# STM32F40x register map
File version: 1.5
Registers are 32-bit, read-write, reset 0x0 unless marked. A register's access mark holds for its fields unless they carry their own. Offsets are from the block's base; [hi:lo] are bit positions; {n}, {i} and the like mark numbered series.

## RNG（随机数发生器） — 真随机数发生器 | Random number generator
Base 0x50060800
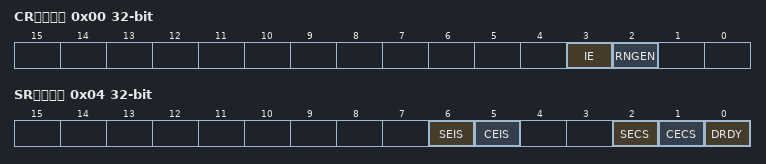
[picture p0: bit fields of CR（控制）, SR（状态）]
0x00 CR（控制） — 随机数使能/中断 | control register
  [3] IE — Interrupt enable
  [2] RNGEN — Random number generator enable
0x04 SR（状态） access per field — 数据就绪/错误标志 | status register
  [6] SEIS rw — Seed error interrupt status
  [5] CEIS rw — Clock error interrupt status
  [2] SECS ro — Seed error current status
  [1] CECS ro — Clock error current status
  [0] DRDY ro — Data ready
0x08 DR（数据） ro — 随机数输出 | data register
  [31:0] RNDATA — Random data

## DCMI（数字摄像头接口） — 数字摄像头接口：并行图像采集 | Digital camera interface
Base 0x50050000
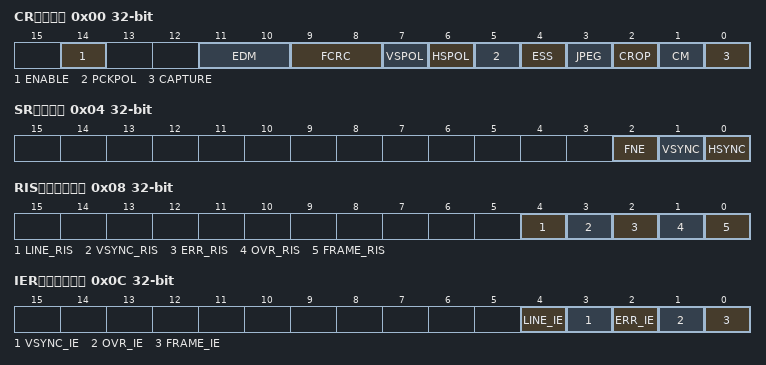
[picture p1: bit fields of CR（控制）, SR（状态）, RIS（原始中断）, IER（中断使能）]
0x00 CR（控制） — 捕获使能/模式/同步 | control register 1
  [14] ENABLE — DCMI enable
  [11:10] EDM — Extended data mode
  [9:8] FCRC — Frame capture rate control
  [7] VSPOL — Vertical synchronization polarity
  [6] HSPOL — Horizontal synchronization polarity
  [5] PCKPOL — Pixel clock polarity
  [4] ESS — Embedded synchronization select
  [3] JPEG — JPEG format
  [2] CROP — Crop feature
  [1] CM — Capture mode
  [0] CAPTURE — Capture enable
0x04 SR（状态） ro — FIFO/同步状态 | status register
  [2] FNE — FIFO not empty
  [1] VSYNC
  [0] HSYNC
0x08 RIS（原始中断） ro — 原始中断状态 | raw interrupt status register
  [4] LINE_RIS — Line raw interrupt status
  [3] VSYNC_RIS — VSYNC raw interrupt status
  [2] ERR_RIS — Synchronization error raw interrupt status
  [1] OVR_RIS — Overrun raw interrupt status
  [0] FRAME_RIS — Capture complete raw interrupt status
0x0C IER（中断使能） — 中断使能 | interrupt enable register
  [4] LINE_IE — Line interrupt enable
  [3] VSYNC_IE — VSYNC interrupt enable
  [2] ERR_IE — Synchronization error interrupt enable
  [1] OVR_IE — Overrun interrupt enable
  [0] FRAME_IE — Capture complete interrupt enable
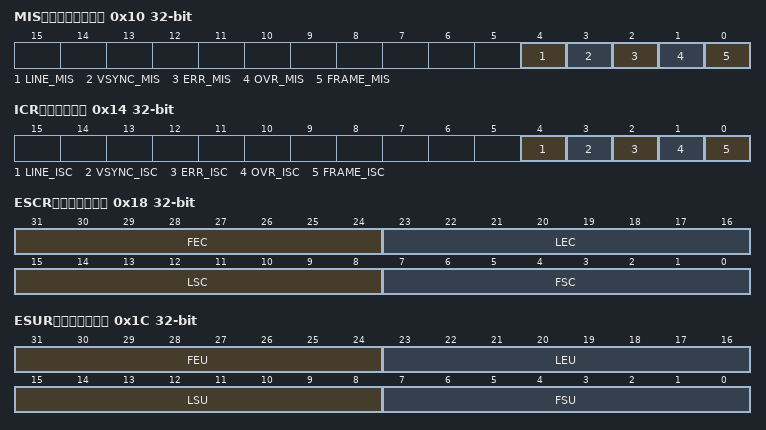
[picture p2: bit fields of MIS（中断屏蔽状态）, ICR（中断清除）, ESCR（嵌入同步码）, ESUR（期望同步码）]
0x10 MIS（中断屏蔽状态） ro — 屏蔽后中断状态 | masked interrupt status register
  [4] LINE_MIS — Line masked interrupt status
  [3] VSYNC_MIS — VSYNC masked interrupt status
  [2] ERR_MIS — Synchronization error masked interrupt status
  [1] OVR_MIS — Overrun masked interrupt status
  [0] FRAME_MIS — Capture complete masked interrupt status
0x14 ICR（中断清除） wo — 清除中断标志 | interrupt clear register
  [4] LINE_ISC — line interrupt status clear
  [3] VSYNC_ISC — Vertical synch interrupt status clear
  [2] ERR_ISC — Synchronization error interrupt status clear
  [1] OVR_ISC — Overrun interrupt status clear
  [0] FRAME_ISC — Capture complete interrupt status clear
0x18 ESCR（嵌入同步码） — 嵌入同步码配置 | embedded synchronization code register
  [31:24] FEC — Frame end delimiter code
  [23:16] LEC — Line end delimiter code
  [15:8] LSC — Line start delimiter code
  [7:0] FSC — Frame start delimiter code
0x1C ESUR（期望同步码） — 期望同步码配置 | embedded synchronization unmask register
  [31:24] FEU — Frame end delimiter unmask
  [23:16] LEU — Line end delimiter unmask
  [15:8] LSU — Line start delimiter unmask
  [7:0] FSU — Frame start delimiter unmask
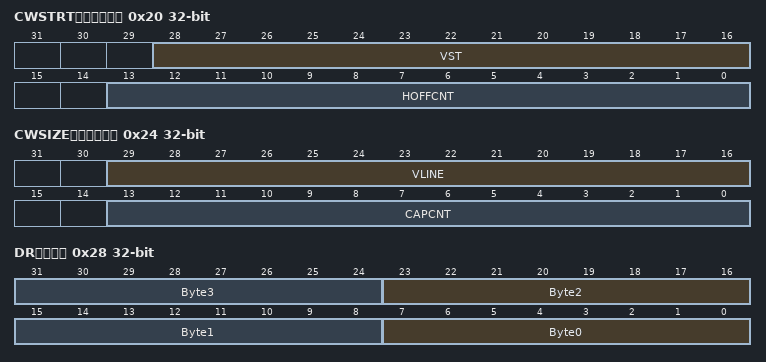
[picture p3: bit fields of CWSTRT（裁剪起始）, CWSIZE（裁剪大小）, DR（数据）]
0x20 CWSTRT（裁剪起始） — 裁剪窗口起始 | crop window start
  [28:16] VST — Vertical start line count
  [13:0] HOFFCNT — Horizontal offset count
0x24 CWSIZE（裁剪大小） — 裁剪窗口大小 | crop window size
  [29:16] VLINE — Vertical line count
  [13:0] CAPCNT — Capture count
0x28 DR（数据） ro — 像素数据 | data register
  [8n+7:8n] Byte{n} (n=0..3) — Data byte {n}

## DBG（调试支持） — 调试支持单元：调试时外设行为控制 | Debug support
Base 0xE0042000
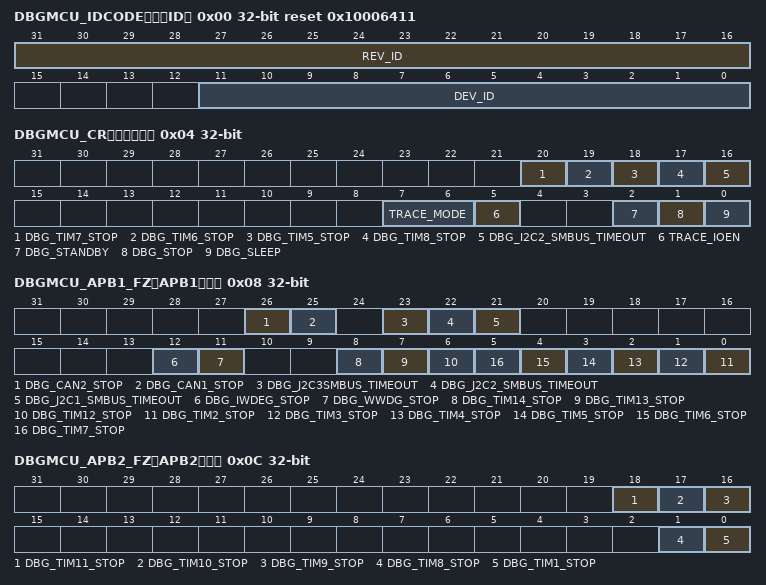
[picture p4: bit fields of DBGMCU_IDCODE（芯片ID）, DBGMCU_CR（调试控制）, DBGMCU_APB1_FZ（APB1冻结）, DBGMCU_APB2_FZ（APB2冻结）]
0x00 DBGMCU_IDCODE（芯片ID） ro reset 0x10006411 — 器件 ID 编码 | IDCODE
  [31:16] REV_ID, [11:0] DEV_ID
0x04 DBGMCU_CR（调试控制） — 调试时 时钟/看门狗/休眠 行为 | Control Register
  [20] DBG_TIM7_STOP, [19] DBG_TIM6_STOP, [18] DBG_TIM5_STOP, [17] DBG_TIM8_STOP, [16] DBG_I2C2_SMBUS_TIMEOUT, [7:6] TRACE_MODE, [5] TRACE_IOEN, [2] DBG_STANDBY, [1] DBG_STOP, [0] DBG_SLEEP
0x08 DBGMCU_APB1_FZ（APB1冻结） — 调试时冻结 APB1 外设 | Debug MCU APB1 Freeze registe
  [26] DBG_CAN2_STOP, [25] DBG_CAN1_STOP, [23] DBG_J2C3SMBUS_TIMEOUT, [22] DBG_J2C2_SMBUS_TIMEOUT, [21] DBG_J2C1_SMBUS_TIMEOUT, [12] DBG_IWDEG_STOP, [11] DBG_WWDG_STOP, [8] DBG_TIM14_STOP, [7] DBG_TIM13_STOP, [6] DBG_TIM12_STOP, [n-2] DBG_TIM{n}_STOP (n=2..7)
0x0C DBGMCU_APB2_FZ（APB2冻结） — 调试时冻结 APB2 外设 | Debug MCU APB2 Freeze registe
  [18] DBG_TIM11_STOP — TIM11 counter stopped when core is halted
  [17] DBG_TIM10_STOP — TIM10 counter stopped when core is halted
  [16] DBG_TIM9_STOP — TIM9 counter stopped when core is halted
  [1] DBG_TIM8_STOP — TIM8 counter stopped when core is halted
  [0] DBG_TIM1_STOP — TIM1 counter stopped when core is halted
